# fcr_me18 register map
Registers are read-write, no defined reset value unless marked. A register's access mark holds for its fields unless they carry their own. Offsets are from the block's base; lines under a group give offsets from that group; [hi:lo] are bit positions; {n}, {i} and the like mark numbered series; 'fields as' and 'values as' point back to an identical list; <NAME> marks a mode.

## Memory map
0x40000800 FCR size 0x400 — Function Control Register.

## FCR — Function Control Register.
Base 0x40000800
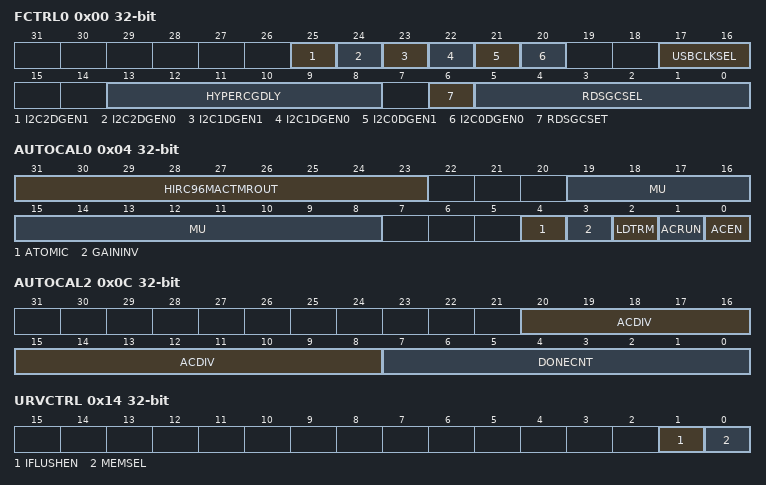
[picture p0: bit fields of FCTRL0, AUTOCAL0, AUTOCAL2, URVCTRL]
0x00 FCTRL0 — Function Control 0.
  [25] I2C2DGEN1 — I2C2 SCL Pad Deglitcher enable.
    0=dis (Deglitcher disabled.); 1=en (Deglitcher enabled.)
  [24] I2C2DGEN0 — I2C2 SDA Pad Deglitcher enable.
    0=dis (Deglitcher disabled.); 1=en (Deglitcher enabled.)
  [23] I2C1DGEN1 — I2C1 SCL Pad Deglitcher enable.
    0=dis (Deglitcher disabled.); 1=en (Deglitcher enabled.)
  [22] I2C1DGEN0 — I2C1 SDA Pad Deglitcher enable.
    0=dis (Deglitcher disabled.); 1=en (Deglitcher enabled.)
  [21] I2C0DGEN1 — I2C0 SCL Pad Deglitcher enable.
    0=dis (Deglitcher disabled.); 1=en (Deglitcher enabled.)
  [20] I2C0DGEN0 — I2C0 SDA Pad Deglitcher enable.
    0=dis (Deglitcher disabled.); 1=en (Deglitcher enabled.)
  [17:16] USBCLKSEL — USB Core Clock Select.
  [13:8] HYPERCGDLY — Hyperbus Clock Generator Delay.
  [6] RDSGCSET — Hyperbus RDS Set.
  [5:0] RDSGCSEL — Hyperbys RDS Gray Code Select.
0x04 AUTOCAL0 — Automatic Calibration 0.
  [31:23] HIRC96MACTMROUT — HIRC96M Trim Value.
  [19:8] MU — MU value.
  [4] ATOMIC — Atomic mode.
    0=not (Not Running.); 1=run (Running.)
  [3] GAININV — Invert Gain.
    0=not (Not Running.); 1=run (Running.)
  [2] LDTRM — Load Trim.
  [1] ACRUN — Autocalibration Run.
    0=not (Not Running.); 1=run (Running.)
  [0] ACEN — Auto-calibration Enable.
    0=dis (Disabled.); 1=en (Enabled.)
0x08 AUTOCAL1 — Automatic Calibration 1.
  [8:0] INITTRM — Initial Trim Setting.
0x0C AUTOCAL2 — Automatic Calibration 2
  [20:8] ACDIV — Auto-callibration Div Setting.
  [7:0] DONECNT — Auto-callibration Done Counter Setting.
0x10 URVBOOTADDR — RISC-V Boot Address.
0x14 URVCTRL — RISC-V Control Register.
  [1] IFLUSHEN — URV instruction flush enable.
  [0] MEMSEL — RAM2, RAM3 exclusive ownership.
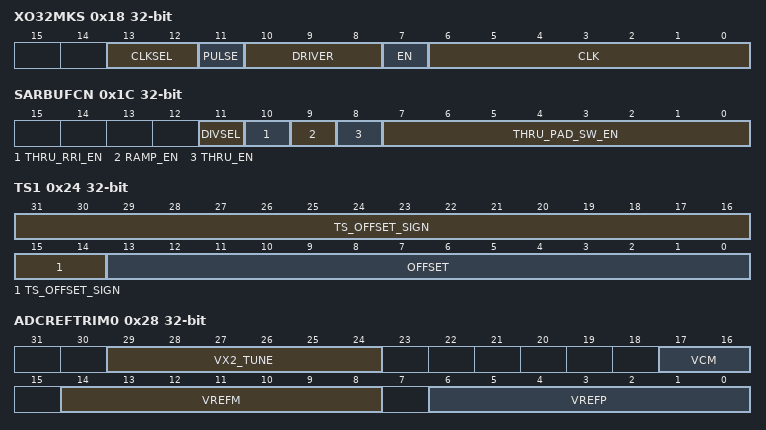
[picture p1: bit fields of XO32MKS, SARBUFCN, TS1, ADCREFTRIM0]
0x18 XO32MKS — RISC-V Control Register.
  [13:12] CLKSEL — Kick Start XO Clock Select
    0=none (No kick start clock.); 1=Test Clock in P1.2 (TMR3[22]=1); 2=ISO (Internal secondary oscilator); 3=IPO (Internal Primary Oscilator)
  [11] PULSE — Kick Start XO 2X Pulse
  [10:8] DRIVER — Kick Start XO Driver
  [7] EN — Kick Start XO Enable
  [6:0] CLK — Kick Start XO Counter Setting
0x1C SARBUFCN
  [11] DIVSEL, [10] THRU_RRI_EN, [9] RAMP_EN, [8] THRU_EN, [7:0] THRU_PAD_SW_EN
0x20 TS0 — Temp Sensor trim0
  [11:0] GAIN — Unsigned gain for temp sensor normalization Temp degrees C = (ADC result * TS_GAIN) + TS_OFFSET.
0x24 TS1 — Temp Sensor trim1
  [31:14] TS_OFFSET_SIGN — Sign extension of TS_OFFSET[13:0]
  [13:0] OFFSET — Signed gain for temp sensor normalization Temp degrees C = (ADC result * TS_GAIN) + TS_OFFSET.
0x28 ADCREFTRIM0 — Temp Sensor trim1
  [29:24] VX2_TUNE — Controls tuning capacitor in fine DAC (offset binary)
  [17:16] VCM — Trimming code for VCM output of reference buffer
  [14:8] VREFM — Trimming code for VREFM output of reference buffer
  [6:0] VREFP — Trimming code for VREFP output of reference buffer
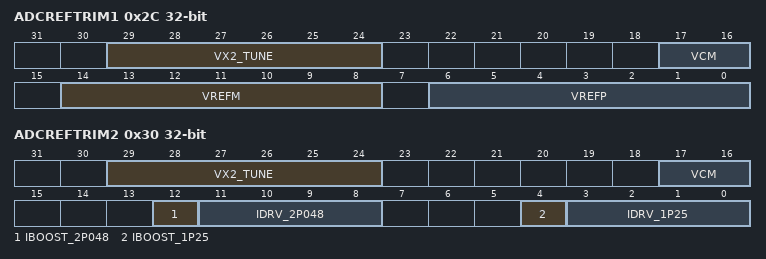
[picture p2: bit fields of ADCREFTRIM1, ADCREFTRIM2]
0x2C ADCREFTRIM1 — Temp Sensor trim1
  fields as ADCREFTRIM0
0x30 ADCREFTRIM2 — Temp Sensor trim1
  [29:24] VX2_TUNE — Controls tuning capacitor in fine DAC (offset binary)
  [17:16] VCM — Trimming code for VCM output of reference buffer
  [12] IBOOST_2P048 — Trimming value for extra drive current in reference buffer outputs. 2.048V
  [11:8] IDRV_2P048 — Trimming code for reference buffer drive strength. 2.048V
  [4] IBOOST_1P25 — Trimming value for extra drive current in reference buffer outputs. 2.048V
  [3:0] IDRV_1P25 — Trimming code for reference buffer drive strength. 1.25V
